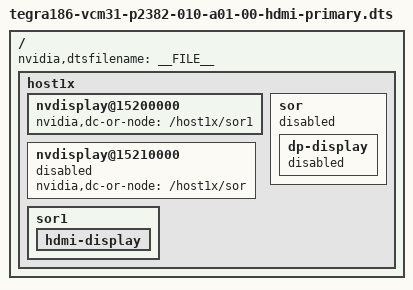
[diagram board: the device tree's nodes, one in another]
/*
 * tegra186-vcm31-p2382-010-a01-00-hdmi-primary.dts: P2382(sunstreaker) dts
 *
 * Copyright (c) 2015, NVIDIA CORPORATION.  All rights reserved.
 *
 * This program is free software; you can redistribute it and/or modify
 * it under the terms of the GNU General Public License as published by
 * the Free Software Foundation; version 2 of the License.
 *
 * This program is distributed in the hope that it will be useful, but WITHOUT
 * ANY WARRANTY; without even the implied warranty of MERCHANTABILITY or
 * FITNESS FOR A PARTICULAR PURPOSE.  See the GNU General Public License for
 * more details.
 */

#include "tegra186-priv-vcm31-p2382-010-a01-00-base.dts"

/ {
	nvidia,dtsfilename = __FILE__;

	host1x {
		nvdisplay@15200000 {
			nvidia,dc-or-node = "/host1x/sor1";
		};

		nvdisplay@15210000 {
			status = "disabled";
			nvidia,dc-or-node = "/host1x/sor";
		};

		sor {
			status = "disabled";
			dp-display {
				status = "disabled";
			};
		};

		sor1 {
			status = "okay";
			hdmi-display {
				status = "okay";
			};
		};
	};
};
